VERSION ""
NS_ :

BU_: STM32L432KC BMS

BO_ 256 READ_CELL_VOLTAGE_REQ: 8 BMS
 SG_ CellNumber : 0|8@1+ (1,0) [1|16] "cell" Vector__XXX

BO_ 257 READ_CELL_VOLTAGE_RESP: 8 BMS
 SG_ CellNumber : 0|8@1+ (1,0) [1|16] "cell" Vector__XXX
 SG_ CellVoltage_mV : 8|16@1+ (1,0) [0|5000] "mV" Vector__XXX

BO_ 258 READ_STACK_VOLTAGE_REQ: 8 BMS
 SG_ Reserved : 0|8@1+ (1,0) [0|255] "" Vector__XXX

BO_ 259 READ_STACK_VOLTAGE_RESP: 8 BMS
 SG_ StackVoltage_mV : 0|16@1+ (1,0) [0|70000] "mV" Vector__XXX

BO_ 260 CAN_ID_READ_TEMP_THRESHOLDS_REQ: 8 BMS
 SG_ Reserved : 0|8@1+ (1,0) [0|255] "" Vector__XXX

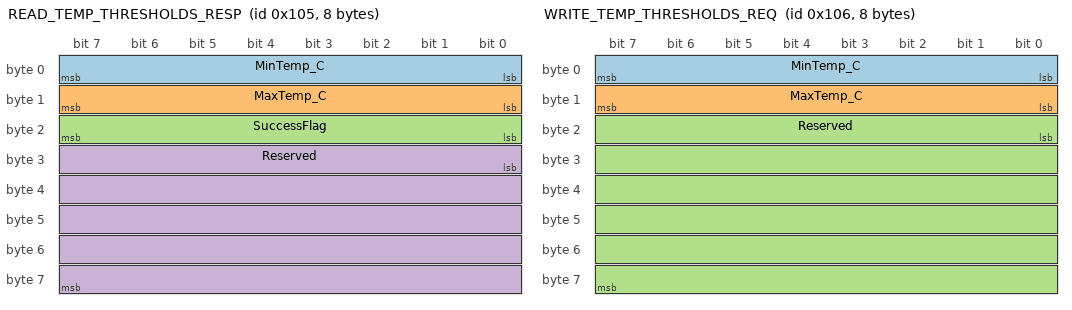
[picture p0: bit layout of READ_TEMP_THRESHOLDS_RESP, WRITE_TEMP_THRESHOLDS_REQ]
BO_ 261 READ_TEMP_THRESHOLDS_RESP: 8 BMS
 SG_ MinTemp_C : 0|8@1- (1,0) [-40|120] "degC" Vector__XXX
 SG_ MaxTemp_C : 8|8@1- (1,0) [-40|120] "degC" Vector__XXX
 SG_ SuccessFlag : 16|8@1+ (1,0) [0|1] "" Vector__XXX
 SG_ Reserved : 24|40@1+ (1,0) [0|0] "" Vector__XXX

BO_ 262 WRITE_TEMP_THRESHOLDS_REQ: 8 BMS
 SG_ MinTemp_C : 0|8@1- (1,0) [-40|120] "degC" Vector__XXX
 SG_ MaxTemp_C : 8|8@1- (1,0) [-40|120] "degC" Vector__XXX
 SG_ Reserved : 16|48@1+ (1,0) [0|0] "" Vector__XXX

BO_ 263 WRITE_TEMP_THRESHOLDS_RESP: 8 BMS
 SG_ SuccessFlag : 0|8@1+ (1,0) [0|1] "" Vector__XXX
 SG_ Reserved : 8|56@1+ (1,0) [0|0] "" Vector__XXX

BO_ 264 WRITE_CELL_BALANCE_REQ: 8 BMS
 SG_ CellMask : 0|16@1+ (1,0) [0|65535] "" Vector__XXX
 SG_ Reserved : 16|48@1+ (1,0) [0|0] "" Vector__XXX

BO_ 265 WRITE_CELL_BALANCE_RESP: 8 BMS
 SG_ SuccessFlag : 0|8@1+ (1,0) [0|1] "" Vector__XXX
 SG_ Reserved : 8|56@1+ (1,0) [0|0] "" Vector__XXX

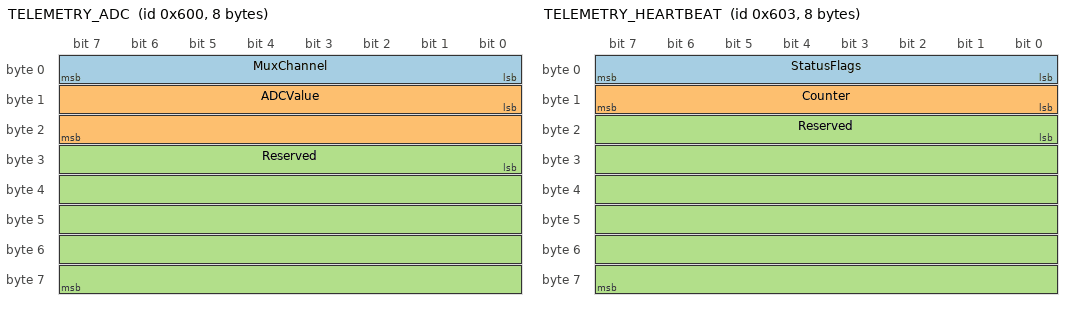
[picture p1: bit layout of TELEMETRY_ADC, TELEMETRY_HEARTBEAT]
BO_ 1536 TELEMETRY_ADC: 8 BMS
 SG_ MuxChannel : 0|8@1+ (1,0) [0|7] "" Vector__XXX
 SG_ ADCValue : 8|16@1+ (1,0) [0|4095] "" Vector__XXX
 SG_ Reserved : 24|40@1+ (1,0) [0|0] "" Vector__XXX

BO_ 1537 TELEMETRY_STACK_VOLTAGE: 8 BMS
 SG_ StackVoltage_mV : 0|16@1+ (1,0) [0|70000] "mV" Vector__XXX
 SG_ Reserved : 16|48@1+ (1,0) [0|0] "" Vector__XXX

BO_ 1538 CELL_VOLTAGES: 8 BMS
 SG_ MUX_INDEX M : 0|2@1+ (1,0) [0|3] "" Vector__XXX
 SG_ Cell1_mV m0 : 2|14@1+ (1,0) [0|16383] "mV" Vector__XXX
 SG_ Cell2_mV m0 : 16|14@1+ (1,0) [0|16383] "mV" Vector__XXX
 SG_ Cell3_mV m0 : 30|14@1+ (1,0) [0|16383] "mV" Vector__XXX
 SG_ Cell4_mV m0 : 44|14@1+ (1,0) [0|16383] "mV" Vector__XXX
 SG_ Cell5_mV m1 : 2|14@1+ (1,0) [0|16383] "mV" Vector__XXX
 SG_ Cell6_mV m1 : 16|14@1+ (1,0) [0|16383] "mV" Vector__XXX
 SG_ Cell7_mV m1 : 30|14@1+ (1,0) [0|16383] "mV" Vector__XXX
 SG_ Cell8_mV m1 : 44|14@1+ (1,0) [0|16383] "mV" Vector__XXX
 SG_ Cell9_mV m2 : 2|14@1+ (1,0) [0|16383] "mV" Vector__XXX
 SG_ Cell10_mV m2 : 16|14@1+ (1,0) [0|16383] "mV" Vector__XXX
 SG_ Cell11_mV m2 : 30|14@1+ (1,0) [0|16383] "mV" Vector__XXX
 SG_ Cell12_mV m2 : 44|14@1+ (1,0) [0|16383] "mV" Vector__XXX
 SG_ Cell13_mV m3 : 2|14@1+ (1,0) [0|16383] "mV" Vector__XXX
 SG_ Cell14_mV m3 : 16|14@1+ (1,0) [0|16383] "mV" Vector__XXX
 SG_ Cell15_mV m3 : 30|14@1+ (1,0) [0|16383] "mV" Vector__XXX
 SG_ Cell16_mV m3 : 44|14@1+ (1,0) [0|16383] "mV" Vector__XXX

VAL_ 1538 MUX_INDEX 0 "01-04" 1 "05-08" 2 "09-12" 3 "13-16";

BO_ 1539 TELEMETRY_HEARTBEAT: 8 BMS
 SG_ StatusFlags : 0|8@1+ (1,0) [0|255] "" Vector__XXX
 SG_ Counter : 8|8@1+ (1,0) [0|255] "" Vector__XXX
 SG_ Reserved : 16|48@1+ (1,0) [0|0] "" Vector__XXX

BO_ 1792 ERROR_DEBUG: 8 BMS
 SG_ ErrorCode : 0|8@1+ (1,0) [0|255] "" Vector__XXX
 SG_ Reserved : 8|56@1+ (1,0) [0|0] "" Vector__XXX

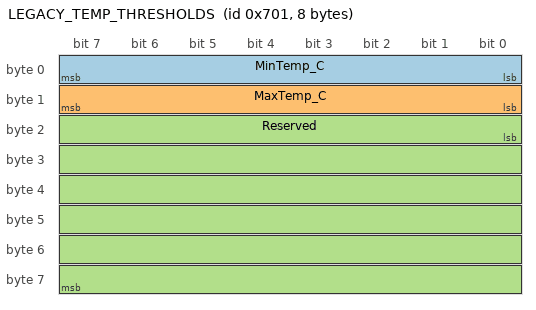
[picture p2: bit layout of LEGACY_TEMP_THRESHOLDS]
BO_ 1793 LEGACY_TEMP_THRESHOLDS: 8 BMS
 SG_ MinTemp_C : 0|8@1- (1,0) [-40|120] "degC" Vector__XXX
 SG_ MaxTemp_C : 8|8@1- (1,0) [-40|120] "degC" Vector__XXX
 SG_ Reserved : 16|48@1+ (1,0) [0|0] "" Vector__XXX

CM_ BO_ 256 "Request cell voltage for a specific cell";
CM_ BO_ 257 "Response with cell voltage for requested cell";
CM_ BO_ 260 "Request current temperature thresholds";
CM_ BO_ 261 "Response with current min/max temperature thresholds";
CM_ BO_ 262 "Set new temperature thresholds";
CM_ BO_ 263 "Response to temperature threshold write";
CM_ BO_ 1536 "ADC thermistor reading for selected MUX channel";
CM_ BO_ 1537 "Stack voltage telemetry";
CM_ BO_ 1538 "All cell voltages (multiplexed: 0=cells 1-3, 1=cells 4-6, 2=cells 7-9, 3=cells 10-12, 4=cells 13-15, 5=cell 16)";
CM_ BO_ 1539 "System heartbeat/status";
CM_ BO_ 1792 "Error/debug message";
CM_ BO_ 1793 "Legacy temperature threshold command (backward compatibilitxy)";
